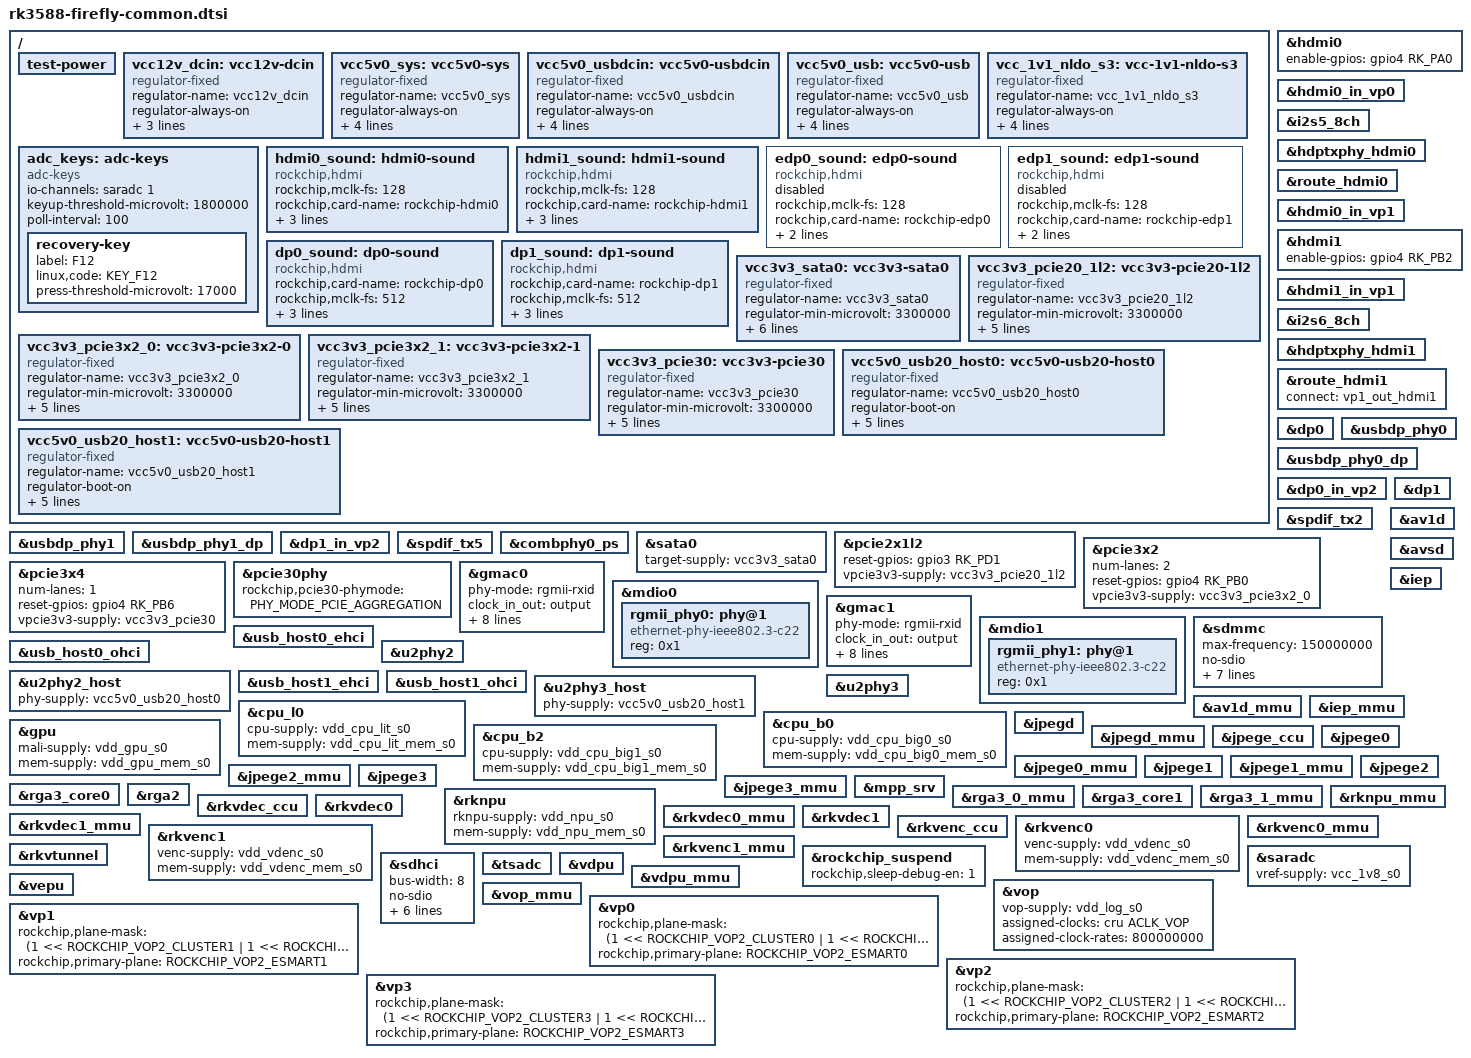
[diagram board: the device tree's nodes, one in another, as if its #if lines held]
// SPDX-License-Identifier: (GPL-2.0+ OR MIT)
/*
 * Copyright (c) 2021 Rockchip Electronics Co., Ltd.
 *
 */

#include "dt-bindings/usb/pd.h"

#ifdef rk3588
#include "rk3588.dtsi"
#else
#include "rk3588s.dtsi"
#endif

#include "rk3588-firefly-rk806-single.dtsi"
#include <dt-bindings/gpio/gpio.h>
#include <dt-bindings/pwm/pwm.h>
#include <dt-bindings/pinctrl/rockchip.h>
#include <dt-bindings/input/rk-input.h>
#include <dt-bindings/display/drm_mipi_dsi.h>
#include <dt-bindings/display/rockchip_vop.h>
#include <dt-bindings/sensor-dev.h>

#include "rk3588-linux.dtsi"

/ {
	test-power {
		status = "okay";
	};

	vcc12v_dcin: vcc12v-dcin {
		compatible = "regulator-fixed";
		regulator-name = "vcc12v_dcin";
		regulator-always-on;
		regulator-boot-on;
		regulator-min-microvolt = <12000000>;
		regulator-max-microvolt = <12000000>;
	};

	vcc5v0_sys: vcc5v0-sys {
		compatible = "regulator-fixed";
		regulator-name = "vcc5v0_sys";
		regulator-always-on;
		regulator-boot-on;
		regulator-min-microvolt = <5000000>;
		regulator-max-microvolt = <5000000>;
		vin-supply = <&vcc12v_dcin>;
	};

	vcc5v0_usbdcin: vcc5v0-usbdcin {
		compatible = "regulator-fixed";
		regulator-name = "vcc5v0_usbdcin";
		regulator-always-on;
		regulator-boot-on;
		regulator-min-microvolt = <5000000>;
		regulator-max-microvolt = <5000000>;
		vin-supply = <&vcc12v_dcin>;
	};

	vcc5v0_usb: vcc5v0-usb {
		compatible = "regulator-fixed";
		regulator-name = "vcc5v0_usb";
		regulator-always-on;
		regulator-boot-on;
		regulator-min-microvolt = <5000000>;
		regulator-max-microvolt = <5000000>;
		vin-supply = <&vcc5v0_usbdcin>;
	};

	vcc_1v1_nldo_s3: vcc-1v1-nldo-s3 {
		compatible = "regulator-fixed";
		regulator-name = "vcc_1v1_nldo_s3";
		regulator-always-on;
		regulator-boot-on;
		regulator-min-microvolt = <1100000>;
		regulator-max-microvolt = <1100000>;
		vin-supply = <&vcc5v0_sys>;
	};

#ifdef FF_RECOVERY_KEY
	adc_keys: adc-keys {
		status = "okay";
		compatible = "adc-keys";
		io-channels = <&saradc 1>;
		io-channel-names = "buttons";
		keyup-threshold-microvolt = <1800000>;
		poll-interval = <100>;

		recovery-key{
			label = "F12";
			linux,code = <KEY_F12>;
			press-threshold-microvolt = <17000>;
		};
	};
#endif

#ifdef FF_HDMI0
	hdmi0_sound: hdmi0-sound {
		status = "okay";
		compatible = "rockchip,hdmi";
		rockchip,mclk-fs = <128>;
		rockchip,card-name = "rockchip-hdmi0";
		rockchip,cpu = <&i2s5_8ch>;
		rockchip,codec = <&hdmi0>;
		rockchip,jack-det;
	};
#endif

#ifdef FF_HDMI1
	hdmi1_sound: hdmi1-sound {
		status = "okay";
		compatible = "rockchip,hdmi";
		rockchip,mclk-fs = <128>;
		rockchip,card-name = "rockchip-hdmi1";
		rockchip,cpu = <&i2s6_8ch>;
		rockchip,codec = <&hdmi1>;
		rockchip,jack-det;
	};
#endif

#ifdef FF_EDP0
	edp0_sound: edp0-sound {
		status = "disabled";
		compatible = "rockchip,hdmi";
		rockchip,mclk-fs = <128>;
		rockchip,card-name = "rockchip-edp0";
		rockchip,cpu = <&i2s5_8ch>;
		rockchip,codec = <&edp0 0>;
	};
#endif

#ifdef FF_EDP1
	edp1_sound: edp1-sound {
		status = "disabled";
		compatible = "rockchip,hdmi";
		rockchip,mclk-fs = <128>;
		rockchip,card-name = "rockchip-edp1";
		rockchip,cpu = <&i2s6_8ch>;
		rockchip,codec = <&edp1 0>;
	};
#endif

#ifdef FF_DP0
	dp0_sound: dp0-sound {
		status = "okay";
		compatible = "rockchip,hdmi";
		rockchip,card-name= "rockchip-dp0";
		rockchip,mclk-fs = <512>;
		rockchip,cpu = <&spdif_tx2>;
		rockchip,codec = <&dp0 1>;
		rockchip,jack-det;
	};
#endif

#ifdef FF_DP1
	dp1_sound: dp1-sound {
		status = "okay";
		compatible = "rockchip,hdmi";
		rockchip,card-name= "rockchip-dp1";
		rockchip,mclk-fs = <512>;
		rockchip,cpu = <&spdif_tx5>;
		rockchip,codec = <&dp1 1>;
		rockchip,jack-det;
	};
#endif

#if defined(FF_SATA0) && !defined(FF_PCIE2_1L2)
	vcc3v3_sata0: vcc3v3-sata0 {
		status = "okay";
		compatible = "regulator-fixed";
		regulator-name = "vcc3v3_sata0";
		regulator-min-microvolt = <3300000>;
		regulator-max-microvolt = <3300000>;
		regulator-boot-on;
		enable-active-high;
		gpio = <&gpio1 RK_PD7 GPIO_ACTIVE_HIGH>;
		startup-delay-us = <5000>;
		vin-supply = <&vcc12v_dcin>;
	};
#endif

#if defined(FF_PCIE2_1L2) && !defined(FF_SATA0)
	vcc3v3_pcie20_1l2: vcc3v3-pcie20-1l2 {
		status = "okay";
		compatible = "regulator-fixed";
		regulator-name = "vcc3v3_pcie20_1l2";
		regulator-min-microvolt = <3300000>;
		regulator-max-microvolt = <3300000>;
		enable-active-high;
		gpio = <&gpio1 RK_PD7 GPIO_ACTIVE_HIGH>;
		startup-delay-us = <5000>;
		vin-supply = <&vcc12v_dcin>;
	};
#endif

#ifdef FF_PCIE3_X2
	vcc3v3_pcie3x2_0: vcc3v3-pcie3x2-0 {
		status = "okay";
		compatible = "regulator-fixed";
		regulator-name = "vcc3v3_pcie3x2_0";
		regulator-min-microvolt = <3300000>;
		regulator-max-microvolt = <3300000>;
		enable-active-high;
		gpio = <&gpio2 RK_PC5 GPIO_ACTIVE_HIGH>;
		startup-delay-us = <5000>;
		vin-supply = <&vcc12v_dcin>;
	};

	vcc3v3_pcie3x2_1: vcc3v3-pcie3x2-1 {
		status = "okay";
		compatible = "regulator-fixed";
		regulator-name = "vcc3v3_pcie3x2_1";
		regulator-min-microvolt = <3300000>;
		regulator-max-microvolt = <3300000>;
		enable-active-high;
		gpio = <&gpio2 RK_PC5 GPIO_ACTIVE_HIGH>;
		startup-delay-us = <5000>;
		vin-supply = <&vcc12v_dcin>;
	};
#endif

#ifdef FF_PCIE3_X4
	vcc3v3_pcie30: vcc3v3-pcie30 {
		status = "okay";
		compatible = "regulator-fixed";
		regulator-name = "vcc3v3_pcie30";
		regulator-min-microvolt = <3300000>;
		regulator-max-microvolt = <3300000>;
		enable-active-high;
		gpio = <&gpio2 RK_PC5 GPIO_ACTIVE_HIGH>;
		startup-delay-us = <5000>;
		vin-supply = <&vcc12v_dcin>;
	};
#endif

#ifdef FF_USB20_HOST0
	vcc5v0_usb20_host0: vcc5v0-usb20-host0 {
		status = "okay";
		compatible = "regulator-fixed";
		regulator-name = "vcc5v0_usb20_host0";
		regulator-boot-on;
		regulator-always-on;
		regulator-min-microvolt = <5000000>;
		regulator-max-microvolt = <5000000>;
		enable-active-high;
		vin-supply = <&vcc5v0_usb>;
	};
#endif

#ifdef FF_USB20_HOST1
	vcc5v0_usb20_host1: vcc5v0-usb20-host1 {
		status = "okay";
		compatible = "regulator-fixed";
		regulator-name = "vcc5v0_usb20_host1";
		regulator-boot-on;
		regulator-always-on;
		regulator-min-microvolt = <5000000>;
		regulator-max-microvolt = <5000000>;
		enable-active-high;
		vin-supply = <&vcc5v0_usb>;
	};
#endif

};

#ifdef FF_HDMI0
&hdmi0 {
	enable-gpios = <&gpio4 RK_PA0 GPIO_ACTIVE_HIGH>;
	status = "okay";
};

&hdmi0_in_vp0 {
	status = "okay";
};

&i2s5_8ch {
	status = "okay";
};

&hdptxphy_hdmi0 {
	status = "okay";
};

&route_hdmi0{
	status = "okay";
};
#endif

// HDMI0 8K display
#if defined(FF_HDMI0) && !defined(FF_HDMI1)
&hdmi0_in_vp1 {
	status = "okay";
};
#endif

#ifdef FF_HDMI1
&hdmi1 {
	enable-gpios = <&gpio4 RK_PB2 GPIO_ACTIVE_HIGH>;
	status = "okay";
};

&hdmi1_in_vp1 {
	status = "okay";
};

&i2s6_8ch {
	status = "okay";
};

&hdptxphy_hdmi1 {
	status = "okay";
};

&route_hdmi1{
	status = "okay";
	connect = <&vp1_out_hdmi1>;
};
#endif

#ifdef FF_DP0
&dp0 {
	status = "okay";
};

&usbdp_phy0 {
	status = "okay";
};

&usbdp_phy0_dp {
	status = "okay";
};

&dp0_in_vp2 {
	status = "okay";
};

&spdif_tx2{
	status = "okay";
};
#endif

#ifdef FF_DP1
&dp1 {
	status = "okay";
};

&usbdp_phy1 {
	status = "okay";
};

&usbdp_phy1_dp {
	status = "okay";
};

&dp1_in_vp2 {
	status = "okay";
};

&spdif_tx5{
	status = "okay";
};
#endif

#if defined(FF_SATA0) && !defined(FF_PCIE2_1L2)
&combphy0_ps {
	status = "okay";
};

&sata0 {
	status = "okay";
	target-supply = <&vcc3v3_sata0>;
};
#endif

#if defined(FF_PCIE2_1L2) && !defined(FF_SATA0)
&combphy0_ps {
	status = "okay";
};

&pcie2x1l2 {
	status = "okay";
	reset-gpios = <&gpio3 RK_PD1 GPIO_ACTIVE_HIGH>;
	vpcie3v3-supply = <&vcc3v3_pcie20_1l2>;
};
#endif

#ifdef FF_PCIE3_X2
&pcie3x2 {
       status = "okay";
       num-lanes = <2>;
       reset-gpios = <&gpio4 RK_PB0 GPIO_ACTIVE_HIGH>;
       vpcie3v3-supply = <&vcc3v3_pcie3x2_0>;
};

&pcie3x4 {
        num-lanes = <1>;
        reset-gpios = <&gpio4 RK_PB6 GPIO_ACTIVE_HIGH>;
        vpcie3v3-supply = <&vcc3v3_pcie3x2_1>;
        status = "okay";
};

&pcie30phy {
       rockchip,pcie30-phymode = <PHY_MODE_PCIE_NANBBI>;
	   status = "okay";
};
#endif

#ifdef FF_PCIE3_X4
&pcie30phy {
	status = "okay";
	rockchip,pcie30-phymode = <PHY_MODE_PCIE_AGGREGATION>;
};

&pcie3x4 {
	status = "okay";
	reset-gpios = <&gpio4 RK_PB6 GPIO_ACTIVE_HIGH>;
	vpcie3v3-supply = <&vcc3v3_pcie30>;
};
#endif

#ifdef FF_GMAC0
&gmac0 {
	status = "okay";
	/* Use rgmii-rxid mode to disable rx delay inside Soc */
	phy-mode = "rgmii-rxid";
	clock_in_out = "output";

	snps,reset-gpio = <&gpio3 RK_PC7 GPIO_ACTIVE_LOW>;
	snps,reset-active-low;
	/* Reset time is 20ms, 100ms for rtl8211f */
	snps,reset-delays-us = <0 20000 100000>;

	pinctrl-names = "default";
	pinctrl-0 = <&gmac0_miim
			&gmac0_tx_bus2
			&gmac0_rx_bus2
			&gmac0_rgmii_clk
			&gmac0_rgmii_bus>;

	tx_delay = <0x45>;
	//rx_delay = <0x4a>;

	phy-handle = <&rgmii_phy0>;
};

&mdio0 {
	rgmii_phy0: phy@1 {
		compatible = "ethernet-phy-ieee802.3-c22";
		reg = <0x1>;
	};
};
#endif

#ifdef FF_GMAC1
&gmac1 {
	status = "okay";
	/* Use rgmii-rxid mode to disable rx delay inside Soc */
	phy-mode = "rgmii-rxid";
	clock_in_out = "output";

	snps,reset-gpio = <&gpio3 RK_PB7 GPIO_ACTIVE_LOW>;
	snps,reset-active-low;
	/* Reset time is 20ms, 100ms for rtl8211f */
	snps,reset-delays-us = <0 20000 100000>;

	pinctrl-names = "default";
	pinctrl-0 = <&gmac1_miim
			&gmac1_tx_bus2
			&gmac1_rx_bus2
			&gmac1_rgmii_clk
			&gmac1_rgmii_bus>;

	tx_delay = <0x42>;
	//rx_delay = <0x4f>;

	phy-handle = <&rgmii_phy1>;
};

&mdio1 {
	rgmii_phy1: phy@1 {
		compatible = "ethernet-phy-ieee802.3-c22";
		reg = <0x1>;
	};
};
#endif

#ifdef FF_SDCARD
&sdmmc {
	status = "okay";
	max-frequency = <150000000>;
	no-sdio;
	no-mmc;
	bus-width = <4>;
	cap-mmc-highspeed;
	cap-sd-highspeed;
	disable-wp;
	sd-uhs-sdr104;
	vqmmc-supply = <&vccio_sd_s0>;
};
#endif

#ifdef FF_USB20_HOST0
&usb_host0_ehci {
        status = "okay";
};

&usb_host0_ohci {
        status = "okay";
};

&u2phy2 {
        status = "okay";
};

&u2phy2_host {
        status = "okay";
	phy-supply = <&vcc5v0_usb20_host0>;
};
#endif

#ifdef FF_USB20_HOST1
&usb_host1_ehci {
        status = "okay";
};

&usb_host1_ohci {
        status = "okay";
};

&u2phy3 {
        status = "okay";
};

&u2phy3_host {
        status = "okay";
	phy-supply = <&vcc5v0_usb20_host1>;
};
#endif

&av1d {
	status = "okay";
};

&av1d_mmu {
	status = "okay";
};

&avsd {
	status = "okay";
};

&cpu_l0 {
	cpu-supply = <&vdd_cpu_lit_s0>;
	mem-supply = <&vdd_cpu_lit_mem_s0>;
};

&cpu_b0 {
	cpu-supply = <&vdd_cpu_big0_s0>;
	mem-supply = <&vdd_cpu_big0_mem_s0>;
};

&cpu_b2 {
	cpu-supply = <&vdd_cpu_big1_s0>;
	mem-supply = <&vdd_cpu_big1_mem_s0>;
};

&gpu {
	mali-supply = <&vdd_gpu_s0>;
	mem-supply = <&vdd_gpu_mem_s0>;
	status = "okay";
};

&iep {
	status = "okay";
};

&iep_mmu {
	status = "okay";
};

&jpegd {
	status = "okay";
};

&jpegd_mmu {
	status = "okay";
};

&jpege_ccu {
	status = "okay";
};

&jpege0 {
	status = "okay";
};

&jpege0_mmu {
	status = "okay";
};

&jpege1 {
	status = "okay";
};

&jpege1_mmu {
	status = "okay";
};

&jpege2 {
	status = "okay";
};

&jpege2_mmu {
	status = "okay";
};

&jpege3 {
	status = "okay";
};

&jpege3_mmu {
	status = "okay";
};

&mpp_srv {
	status = "okay";
};

&rga3_core0 {
	status = "okay";
};

&rga3_0_mmu {
	status = "okay";
};

&rga3_core1 {
	status = "okay";
};

&rga3_1_mmu {
	status = "okay";
};

&rga2 {
	status = "okay";
};

&rknpu {
	rknpu-supply = <&vdd_npu_s0>;
	mem-supply = <&vdd_npu_mem_s0>;
	status = "okay";
};

&rknpu_mmu {
	status = "okay";
};

&rkvdec_ccu {
	status = "okay";
};

&rkvdec0 {
	status = "okay";
};

&rkvdec0_mmu {
	status = "okay";
};

&rkvdec1 {
	status = "okay";
};

&rkvdec1_mmu {
	status = "okay";
};

&rkvenc_ccu {
	status = "okay";
};

&rkvenc0 {
	venc-supply = <&vdd_vdenc_s0>;
	mem-supply = <&vdd_vdenc_mem_s0>;
	status = "okay";
};

&rkvenc0_mmu {
	status = "okay";
};

&rkvenc1 {
	venc-supply = <&vdd_vdenc_s0>;
	mem-supply = <&vdd_vdenc_mem_s0>;
	status = "okay";
};

&rkvenc1_mmu {
	status = "okay";
};

&rkvtunnel {
	status = "okay";
};

&rockchip_suspend {
	status = "okay";
	rockchip,sleep-debug-en = <1>;
};

&saradc {
	status = "okay";
	vref-supply = <&vcc_1v8_s0>;
};

&sdhci {
	bus-width = <8>;
	no-sdio;
	no-sd;
	non-removable;
	max-frequency = <200000000>;
	mmc-hs400-1_8v;
	mmc-hs400-enhanced-strobe;
	/delete-property/supports-cqe;
	full-pwr-cycle-in-suspend;
	status = "okay";
};

&tsadc {
	status = "okay";
};

&vdpu {
	status = "okay";
};

&vdpu_mmu {
	status = "okay";
};

&vepu {
	status = "okay";
};

&vop {
	status = "okay";
	vop-supply = <&vdd_log_s0>;
	assigned-clocks = <&cru ACLK_VOP>;
	assigned-clock-rates = <800000000>;
};

&vop_mmu {
	status = "okay";
};

/* vp0 & vp1 splice for 8K output */
&vp0 {
	rockchip,plane-mask = <(1 << ROCKCHIP_VOP2_CLUSTER0 | 1 << ROCKCHIP_VOP2_ESMART0)>;
	rockchip,primary-plane = <ROCKCHIP_VOP2_ESMART0>;
};

&vp1 {
	rockchip,plane-mask = <(1 << ROCKCHIP_VOP2_CLUSTER1 | 1 << ROCKCHIP_VOP2_ESMART1)>;
	rockchip,primary-plane = <ROCKCHIP_VOP2_ESMART1>;
};

&vp2 {
	rockchip,plane-mask = <(1 << ROCKCHIP_VOP2_CLUSTER2 | 1 << ROCKCHIP_VOP2_ESMART2)>;
	rockchip,primary-plane = <ROCKCHIP_VOP2_ESMART2>;
};

&vp3 {
	rockchip,plane-mask = <(1 << ROCKCHIP_VOP2_CLUSTER3 | 1 << ROCKCHIP_VOP2_ESMART3)>;
	rockchip,primary-plane = <ROCKCHIP_VOP2_ESMART3>;
};

